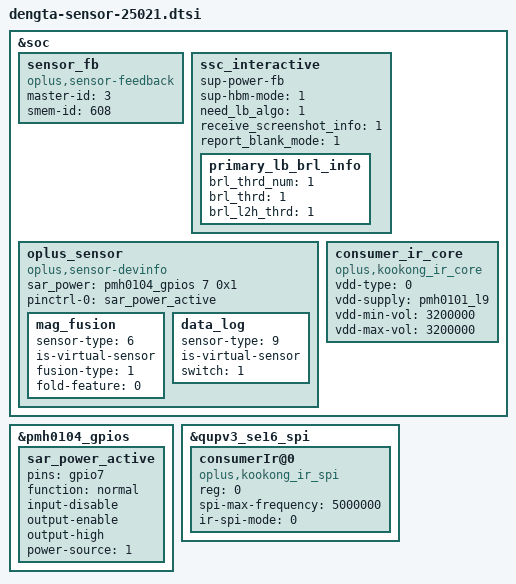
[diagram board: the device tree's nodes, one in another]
/**********************************************************************************
 * Copyright (c)  2022-2025  Guangdong oplus Mobile Comm Corp., Ltd
 * Description: oplus sensor dtsi
 *
 * Version: 1.0
 * Date: 2025-09-16
 *
 * ------------------------------ Revision History: --------------------------------
 * <version>         <date>        <author>                <desc>
 ***********************************************************************************/
#include <dt-bindings/regulator/qcom,rpmh-regulator-levels.h>
&soc {
    //#ifdef OPLUS_FEATURE_SENSOR_SMEM
sensor_fb: sensor_fb {
               compatible = "oplus,sensor-feedback";
               master-id  = <3>;
               smem-id    = <608>;
           };
           ssc_interactive {
               sup-power-fb;
               sup-hbm-mode = <1>;
               need_lb_algo = <1>;
               receive_screenshot_info = <1>;
               report_blank_mode = <1>;

               primary_lb_brl_info {
                    brl_thrd_num = <1>;
                    brl_thrd = <1>;
                    brl_l2h_thrd = <1>;
               };
           };
           oplus_sensor {
               compatible = "oplus,sensor-devinfo";

               sar_power = <&pmh0104_gpios 7 0x1>;
               pinctrl-names = "default";
               pinctrl-0 = <&sar_power_active>;

               /*virtual sensor*/
               mag_fusion {
                   sensor-type = <6>;//OPLUS_MAG_FUSION
                   is-virtual-sensor;
                   fusion-type = <1>;//AKM_FUSION
                   fold-feature = <0>;
               };
               data_log {
                   sensor-type = <9>; // OPLUS_DATA_LOG
                   is-virtual-sensor;
                   switch = <1>;
               };
           };
           consumer_ir_core {
               compatible = "oplus,kookong_ir_core";
               status = "okay";
               vdd-type = <0>; /*0: internal LDO , 1: external LDO*/
               vdd-supply = <&pmh0101_l9>;
               vdd-min-vol = <3200000>;
               vdd-max-vol = <3200000>;
           };
           //#endif /*OPLUS_FEATURE_SENSOR_SMEM*/
};

//add for oplus sar sensor PMH0104J_GPIO07
&pmh0104_gpios {
	sar_power_active: sar_power_active {
		pins = "gpio7";
		function = "normal";
		input-disable;
		output-enable;
		output-high;
		power-source = <1>;
	};
};

//add for oplus consumerIr SPI mode
&qupv3_se16_spi{
    status = "ok";
    consumerIr@0 {
        compatible = "oplus,kookong_ir_spi";
        reg = <0>;
        status = "ok";

        spi-max-frequency = <5000000>;    /*4800000,9600000,15000000,19200000*/
        ir-spi-mode = <0>;
    };
};
